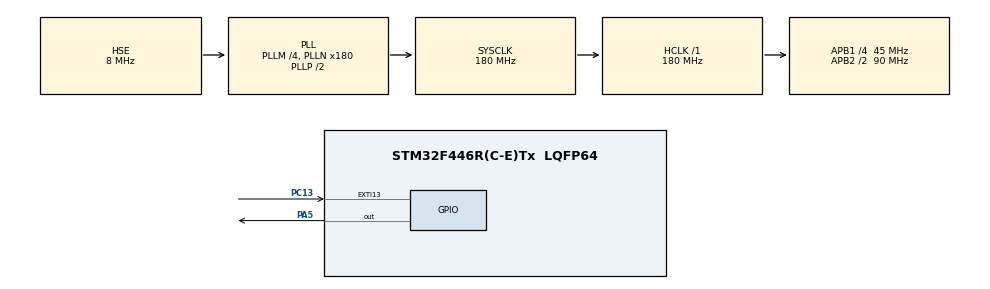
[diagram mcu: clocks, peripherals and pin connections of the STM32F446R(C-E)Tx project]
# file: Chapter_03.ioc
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Mcu.Family=STM32F4
Mcu.Name=STM32F446R(C-E)Tx
Mcu.Package=LQFP64
NUCLEO-F446RE.BUTTON=1
NUCLEO-F446RE.LD1=true
NVIC.PriorityGroup=NVIC_PRIORITYGROUP_0
PA13.GPIO_Label=TMS
PA13.Mode=Trace_Asynchronous_SW
PA13.Signal=SYS_JTMS-SWDIO
PA14.GPIO_Label=TCK
PA14.Mode=Trace_Asynchronous_SW
PA14.Signal=SYS_JTCK-SWCLK
PA2.GPIO_Label=USART_TX
PA2.Signal=USART2_TX
PA3.GPIO_Label=USART_RX
PA3.Signal=USART2_RX
PA5.Signal=GPIO_Output
PB3.GPIO_Label=SWO
PB3.Mode=Trace_Asynchronous_SW
PB3.Signal=SYS_JTDO-SWO
PC13.Signal=GPXTI13
PC14-OSC32_IN.Mode=LSE-External-Oscillator
PC14-OSC32_IN.Signal=RCC_OSC32_IN
PC15-OSC32_OUT.Mode=LSE-External-Oscillator
PC15-OSC32_OUT.Signal=RCC_OSC32_OUT
PH0-OSC_IN.Mode=HSE-External-Clock-Source
PH0-OSC_IN.Signal=RCC_OSC_IN
PH1-OSC_OUT.Mode=HSE-External-Clock-Source
PH1-OSC_OUT.Signal=RCC_OSC_OUT
ProjectManager.HeapSize=0x200
ProjectManager.StackSize=0x400
ProjectManager.TargetToolchain=STM32CubeIDE
RCC.AHBFreq_Value=180000000
RCC.APB1CLKDivider=RCC_HCLK_DIV4
RCC.APB1Freq_Value=45000000
RCC.APB1TimFreq_Value=90000000
RCC.APB2CLKDivider=RCC_HCLK_DIV2
RCC.APB2Freq_Value=90000000
RCC.APB2TimFreq_Value=180000000
RCC.CortexFreq_Value=180000000
RCC.FLatency-AdvancedSettings=FLASH_LATENCY_5
RCC.HCLKFreq_Value=180000000
RCC.HSE_VALUE=8000000
RCC.HSI_VALUE=16000000
RCC.PLLM=4
RCC.PLLN=180
RCC.PLLSourceVirtual=RCC_PLLSOURCE_HSE
RCC.SYSCLKFreq_VALUE=180000000
RCC.SYSCLKSource=RCC_SYSCLKSOURCE_PLLCLK
RCC.USBFreq_Value=180000000
RCC.VCOOutputFreq_Value=360000000
VP_NUCLEO-F446RE_VS_BSP_COMMON.Mode=COMMON
board=NUCLEO-F446RE

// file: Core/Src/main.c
/* USER CODE BEGIN Header */
/**
  ******************************************************************************
  * @file           : main.c
  * @brief          : Main program body
  ******************************************************************************
  * @attention
  *
  * Copyright (c) 2026 STMicroelectronics.
  * All rights reserved.
  *
  * This software is licensed under terms that can be found in the LICENSE file
  * in the root directory of this software component.
  * If no LICENSE file comes with this software, it is provided AS-IS.
  *
  ******************************************************************************
  */
/* USER CODE END Header */
#include "main.h"

/* USER CODE BEGIN Includes */
#include "SEGGER_SYSVIEW.h"
/* USER CODE END Includes */

void SystemClock_Config(void);
static void MX_GPIO_Init(void);

int main(void)
{

  /* USER CODE BEGIN 1 */

  // Declare the loop counter
  uint32_t loopCounter = 0;

  /* USER CODE END 1 */

  /* MCU Configuration--------------------------------------------------------*/

  /* Reset of all peripherals, Initializes the Flash interface and the Systick. */
  HAL_Init();

  /* Configure the system clock */
  SystemClock_Config();

  /* Initialize all configured peripherals */
  MX_GPIO_Init();
  /* USER CODE BEGIN 2 */

  SEGGER_SYSVIEW_Conf();

  /* USER CODE END 2 */

  /* Initialize leds */
  BSP_LED_Init(LED2);

  /* Initialize USER push-button, will be used to trigger an interrupt each time it's pressed.*/
  BSP_PB_Init(BUTTON_USER, BUTTON_MODE_EXTI);

  /* Infinite loop */
  /* USER CODE BEGIN WHILE */
  while (1)
  {
    // The loop counter is just used for demonstrating debugging
    loopCounter++;
    // write a message to the debugger
    SEGGER_SYSVIEW_PrintfHost("Starting loop iteration: %lu", loopCounter);

    // toggle on board led
    BSP_LED_Toggle(LED2);
    // wait one second (1000ms)
    HAL_Delay(1000);

    //write another message to debugger
    SEGGER_SYSVIEW_PrintfHost("Ending loop iteration: %lu", loopCounter);

    /* USER CODE END WHILE */

  }
}

void SystemClock_Config(void)
{
  RCC_OscInitTypeDef RCC_OscInitStruct = {0};
  RCC_ClkInitTypeDef RCC_ClkInitStruct = {0};

  /** Configure the main internal regulator output voltage
  */
  __HAL_RCC_PWR_CLK_ENABLE();
  __HAL_PWR_VOLTAGESCALING_CONFIG(PWR_REGULATOR_VOLTAGE_SCALE1);

  /** Initializes the RCC Oscillators according to the specified parameters
  * in the RCC_OscInitTypeDef structure.
  */
  RCC_OscInitStruct.OscillatorType = RCC_OSCILLATORTYPE_HSE;
  RCC_OscInitStruct.HSEState = RCC_HSE_BYPASS;
  RCC_OscInitStruct.PLL.PLLState = RCC_PLL_ON;
  RCC_OscInitStruct.PLL.PLLSource = RCC_PLLSOURCE_HSE;
  RCC_OscInitStruct.PLL.PLLM = 4;
  RCC_OscInitStruct.PLL.PLLN = 180;
  RCC_OscInitStruct.PLL.PLLP = RCC_PLLP_DIV2;
  RCC_OscInitStruct.PLL.PLLQ = 2;
  RCC_OscInitStruct.PLL.PLLR = 2;
  if (HAL_RCC_OscConfig(&RCC_OscInitStruct) != HAL_OK)
  {
    Error_Handler();
  }

  /** Activate the Over-Drive mode
  */
  if (HAL_PWREx_EnableOverDrive() != HAL_OK)
  {
    Error_Handler();
  }

  /** Initializes the CPU, AHB and APB buses clocks
  */
  RCC_ClkInitStruct.ClockType = RCC_CLOCKTYPE_HCLK|RCC_CLOCKTYPE_SYSCLK
                              |RCC_CLOCKTYPE_PCLK1|RCC_CLOCKTYPE_PCLK2;
  RCC_ClkInitStruct.SYSCLKSource = RCC_SYSCLKSOURCE_PLLCLK;
  RCC_ClkInitStruct.AHBCLKDivider = RCC_SYSCLK_DIV1;
  RCC_ClkInitStruct.APB1CLKDivider = RCC_HCLK_DIV4;
  RCC_ClkInitStruct.APB2CLKDivider = RCC_HCLK_DIV2;

  if (HAL_RCC_ClockConfig(&RCC_ClkInitStruct, FLASH_LATENCY_5) != HAL_OK)
  {
    Error_Handler();
  }
}

static void MX_GPIO_Init(void)
{
  GPIO_InitTypeDef GPIO_InitStruct = {0};

  /* GPIO Ports Clock Enable */
  __HAL_RCC_GPIOC_CLK_ENABLE();
  __HAL_RCC_GPIOH_CLK_ENABLE();
  __HAL_RCC_GPIOA_CLK_ENABLE();
  __HAL_RCC_GPIOB_CLK_ENABLE();

  /*Configure GPIO pins : USART_TX_Pin USART_RX_Pin */
  GPIO_InitStruct.Pin = USART_TX_Pin|USART_RX_Pin;
  GPIO_InitStruct.Mode = GPIO_MODE_AF_PP;
  GPIO_InitStruct.Pull = GPIO_NOPULL;
  GPIO_InitStruct.Speed = GPIO_SPEED_FREQ_VERY_HIGH;
  GPIO_InitStruct.Alternate = GPIO_AF7_USART2;
  HAL_GPIO_Init(GPIOA, &GPIO_InitStruct);

}

void Error_Handler(void)
{
  __disable_irq();
  while (1)
  {
  }
}
